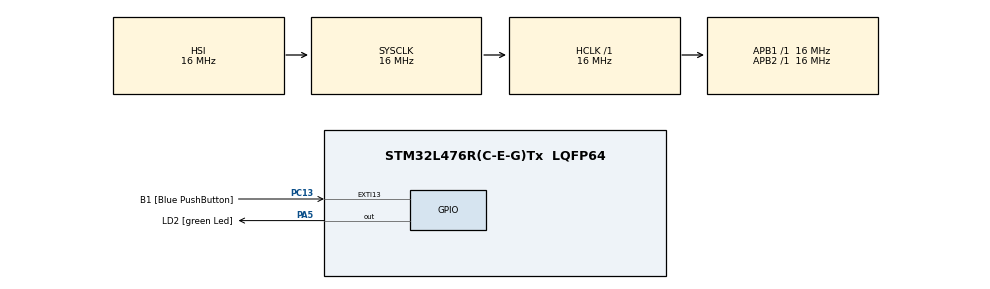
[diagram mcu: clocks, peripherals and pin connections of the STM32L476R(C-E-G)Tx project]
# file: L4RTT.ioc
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Mcu.Family=STM32L4
Mcu.Name=STM32L476R(C-E-G)Tx
Mcu.Package=LQFP64
NVIC.EXTI15_10_IRQn=true\:0\:0\:false\:false\:true\:true\:true\:true
NVIC.PriorityGroup=NVIC_PRIORITYGROUP_4
NVIC.TIM2_IRQn=true\:0\:0\:true\:false\:true\:true\:true\:true
PA13\ (JTMS-SWDIO).GPIO_Label=TMS
PA13\ (JTMS-SWDIO).Mode=Serial_Wire
PA13\ (JTMS-SWDIO).Signal=SYS_JTMS-SWDIO
PA14\ (JTCK-SWCLK).GPIO_Label=TCK
PA14\ (JTCK-SWCLK).Mode=Serial_Wire
PA14\ (JTCK-SWCLK).Signal=SYS_JTCK-SWCLK
PA5.GPIO_Label=LD2 [green Led]
PA5.GPIO_ModeDefaultOutputPP=GPIO_MODE_OUTPUT_PP
PA5.GPIO_PuPd=GPIO_NOPULL
PA5.GPIO_Speed=GPIO_SPEED_FREQ_LOW
PA5.Signal=GPIO_Output
PC13.GPIO_Label=B1 [Blue PushButton]
PC13.GPIO_ModeDefaultEXTI=GPIO_MODE_IT_FALLING
PC13.GPIO_PuPd=GPIO_NOPULL
PC13.Signal=GPXTI13
PC14-OSC32_IN\ (PC14).Mode=LSE-External-Oscillator
PC14-OSC32_IN\ (PC14).Signal=RCC_OSC32_IN
PC15-OSC32_OUT\ (PC15).Mode=LSE-External-Oscillator
PC15-OSC32_OUT\ (PC15).Signal=RCC_OSC32_OUT
ProjectManager.HeapSize=0x200
ProjectManager.StackSize=0x400
ProjectManager.TargetToolchain=STM32CubeIDE
RCC.ADCFreq_Value=16000000
RCC.AHBFreq_Value=16000000
RCC.APB1Freq_Value=16000000
RCC.APB1TimFreq_Value=16000000
RCC.APB2Freq_Value=16000000
RCC.APB2TimFreq_Value=16000000
RCC.CortexFreq_Value=16000000
RCC.HCLKFreq_Value=16000000
RCC.HSE_VALUE=8000000
RCC.HSI_VALUE=16000000
RCC.MSI_VALUE=4000000
RCC.PLLN=10
RCC.PREFETCH_ENABLE=1
RCC.SYSCLKFreq_VALUE=16000000
RCC.SYSCLKSource=RCC_SYSCLKSOURCE_HSI
RCC.USBFreq_Value=16000000
RCC.VCOOutputFreq_Value=40000000
TIM2.Period=1000
TIM2.Prescaler=16000
VP_TIM2_VS_ClockSourceINT.Mode=Internal
board=NUCLEO-L476RG

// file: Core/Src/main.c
/* USER CODE BEGIN Header */
/**
  ******************************************************************************
  * @file           : main.c
  * @brief          : Main program body
  ******************************************************************************
  * @attention
  *
  * Copyright (c) 2022 STMicroelectronics.
  * All rights reserved.
  *
  * This software is licensed under terms that can be found in the LICENSE file
  * in the root directory of this software component.
  * If no LICENSE file comes with this software, it is provided AS-IS.
  *
  ******************************************************************************
  */
/* USER CODE END Header */
#include "main.h"

/* USER CODE BEGIN Includes */
#include "SEGGER_RTT.h"
/* USER CODE END Includes */

/* USER CODE BEGIN PD */
#define VERSION "v1.0.0"
/* USER CODE END PD */

TIM_HandleTypeDef htim2;

void SystemClock_Config(void);
static void MX_GPIO_Init(void);
static void MX_TIM2_Init(void);
/* USER CODE BEGIN PFP */
void RTT_Read(void);
/* USER CODE END PFP */

/* USER CODE BEGIN 0 */
uint8_t m_b1_flag = 0;
uint8_t m_tim2_flag = 0;

uint32_t m_num_b1 = 0;
uint32_t m_num_tim2 = 0;
/* USER CODE END 0 */

int main(void)
{

  /* MCU Configuration--------------------------------------------------------*/

  /* Reset of all peripherals, Initializes the Flash interface and the Systick. */
  HAL_Init();

  /* Configure the system clock */
  SystemClock_Config();

  /* Initialize all configured peripherals */
  MX_GPIO_Init();
  MX_TIM2_Init();
  /* USER CODE BEGIN 2 */
  SEGGER_RTT_ConfigUpBuffer(0, NULL, NULL, 0, SEGGER_RTT_MODE_NO_BLOCK_SKIP);
  SEGGER_RTT_printf(0, "STM32L4 RTT %s\r\n", VERSION);

  HAL_TIM_Base_Start_IT(&htim2);
  /* USER CODE END 2 */

  /* Infinite loop */
  /* USER CODE BEGIN WHILE */
  while (1)
  {
    RTT_Read();

    if (m_b1_flag)
    {
      m_num_b1++;
      SEGGER_RTT_SetTerminal(0);
      SEGGER_RTT_printf(0, " Number of Button Presses: %d\r\n", m_num_b1);
      m_b1_flag = 0;
    }

    if (m_tim2_flag)
    {
      m_num_tim2++;
      SEGGER_RTT_SetTerminal(1);
      SEGGER_RTT_printf(0, " Number of Timer Rings: %d\r\n", m_num_tim2);
      m_tim2_flag = 0;
    }
    /* USER CODE END WHILE */

  }
}

void SystemClock_Config(void)
{
  RCC_OscInitTypeDef RCC_OscInitStruct = {0};
  RCC_ClkInitTypeDef RCC_ClkInitStruct = {0};

  /** Configure the main internal regulator output voltage
  */
  if (HAL_PWREx_ControlVoltageScaling(PWR_REGULATOR_VOLTAGE_SCALE1) != HAL_OK)
  {
    Error_Handler();
  }

  /** Initializes the RCC Oscillators according to the specified parameters
  * in the RCC_OscInitTypeDef structure.
  */
  RCC_OscInitStruct.OscillatorType = RCC_OSCILLATORTYPE_HSI;
  RCC_OscInitStruct.HSIState = RCC_HSI_ON;
  RCC_OscInitStruct.HSICalibrationValue = RCC_HSICALIBRATION_DEFAULT;
  RCC_OscInitStruct.PLL.PLLState = RCC_PLL_NONE;
  if (HAL_RCC_OscConfig(&RCC_OscInitStruct) != HAL_OK)
  {
    Error_Handler();
  }

  /** Initializes the CPU, AHB and APB buses clocks
  */
  RCC_ClkInitStruct.ClockType = RCC_CLOCKTYPE_HCLK|RCC_CLOCKTYPE_SYSCLK
                              |RCC_CLOCKTYPE_PCLK1|RCC_CLOCKTYPE_PCLK2;
  RCC_ClkInitStruct.SYSCLKSource = RCC_SYSCLKSOURCE_HSI;
  RCC_ClkInitStruct.AHBCLKDivider = RCC_SYSCLK_DIV1;
  RCC_ClkInitStruct.APB1CLKDivider = RCC_HCLK_DIV1;
  RCC_ClkInitStruct.APB2CLKDivider = RCC_HCLK_DIV1;

  if (HAL_RCC_ClockConfig(&RCC_ClkInitStruct, FLASH_LATENCY_0) != HAL_OK)
  {
    Error_Handler();
  }
}

static void MX_TIM2_Init(void)
{

  TIM_ClockConfigTypeDef sClockSourceConfig = {0};
  TIM_MasterConfigTypeDef sMasterConfig = {0};

  htim2.Instance = TIM2;
  htim2.Init.Prescaler = 16000;
  htim2.Init.CounterMode = TIM_COUNTERMODE_UP;
  htim2.Init.Period = 1000;
  htim2.Init.ClockDivision = TIM_CLOCKDIVISION_DIV1;
  htim2.Init.AutoReloadPreload = TIM_AUTORELOAD_PRELOAD_DISABLE;
  if (HAL_TIM_Base_Init(&htim2) != HAL_OK)
  {
    Error_Handler();
  }
  sClockSourceConfig.ClockSource = TIM_CLOCKSOURCE_INTERNAL;
  if (HAL_TIM_ConfigClockSource(&htim2, &sClockSourceConfig) != HAL_OK)
  {
    Error_Handler();
  }
  sMasterConfig.MasterOutputTrigger = TIM_TRGO_RESET;
  sMasterConfig.MasterSlaveMode = TIM_MASTERSLAVEMODE_DISABLE;
  if (HAL_TIMEx_MasterConfigSynchronization(&htim2, &sMasterConfig) != HAL_OK)
  {
    Error_Handler();
  }

}

static void MX_GPIO_Init(void)
{
  GPIO_InitTypeDef GPIO_InitStruct = {0};

  /* GPIO Ports Clock Enable */
  __HAL_RCC_GPIOC_CLK_ENABLE();
  __HAL_RCC_GPIOA_CLK_ENABLE();

  /*Configure GPIO pin Output Level */
  HAL_GPIO_WritePin(LD2_GPIO_Port, LD2_Pin, GPIO_PIN_RESET);

  /*Configure GPIO pin : B1_Pin */
  GPIO_InitStruct.Pin = B1_Pin;
  GPIO_InitStruct.Mode = GPIO_MODE_IT_FALLING;
  GPIO_InitStruct.Pull = GPIO_NOPULL;
  HAL_GPIO_Init(B1_GPIO_Port, &GPIO_InitStruct);

  /*Configure GPIO pin : LD2_Pin */
  GPIO_InitStruct.Pin = LD2_Pin;
  GPIO_InitStruct.Mode = GPIO_MODE_OUTPUT_PP;
  GPIO_InitStruct.Pull = GPIO_NOPULL;
  GPIO_InitStruct.Speed = GPIO_SPEED_FREQ_LOW;
  HAL_GPIO_Init(LD2_GPIO_Port, &GPIO_InitStruct);

  /* EXTI interrupt init*/
  HAL_NVIC_SetPriority(EXTI15_10_IRQn, 0, 0);
  HAL_NVIC_EnableIRQ(EXTI15_10_IRQn);

}

/* USER CODE BEGIN 4 */
void RTT_Read(void)
{
  char input;
  uint32_t size = SEGGER_RTT_Read(0, &input, 1u);

  if (size > 0 && input == '0')
  {
    m_num_b1 = 0;
    m_num_tim2 = 0;
  }
}

void HAL_GPIO_EXTI_Callback(uint16_t GPIO_Pin)
{
  if (GPIO_Pin == B1_Pin)
  {
    m_b1_flag = 1;
  }
}

void HAL_TIM_PeriodElapsedCallback(TIM_HandleTypeDef *htim)
{
  m_tim2_flag = 1;
}
/* USER CODE END 4 */

void Error_Handler(void)
{
  __disable_irq();
  while (1)
  {
  }
}
